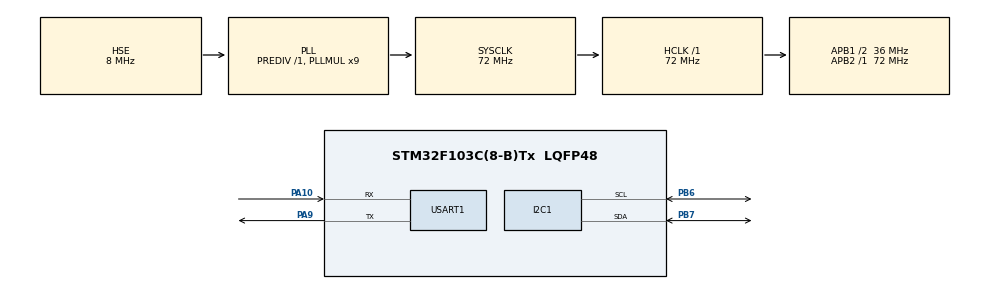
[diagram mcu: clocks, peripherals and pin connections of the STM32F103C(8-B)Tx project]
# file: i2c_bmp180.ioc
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Mcu.Family=STM32F1
Mcu.Name=STM32F103C(8-B)Tx
Mcu.Package=LQFP48
NVIC.PriorityGroup=NVIC_PRIORITYGROUP_4
PA10.Mode=Asynchronous
PA10.Signal=USART1_RX
PA13.Mode=Serial_Wire
PA13.Signal=SYS_JTMS-SWDIO
PA14.Mode=Serial_Wire
PA14.Signal=SYS_JTCK-SWCLK
PA9.Mode=Asynchronous
PA9.Signal=USART1_TX
PB6.Mode=I2C
PB6.Signal=I2C1_SCL
PB7.Mode=I2C
PB7.Signal=I2C1_SDA
PD0-OSC_IN.Mode=HSE-External-Oscillator
PD0-OSC_IN.Signal=RCC_OSC_IN
PD1-OSC_OUT.Mode=HSE-External-Oscillator
PD1-OSC_OUT.Signal=RCC_OSC_OUT
ProjectManager.HeapSize=0x200
ProjectManager.StackSize=0x400
ProjectManager.TargetToolchain=STM32CubeIDE
RCC.AHBFreq_Value=72000000
RCC.APB1CLKDivider=RCC_HCLK_DIV2
RCC.APB1Freq_Value=36000000
RCC.APB1TimFreq_Value=72000000
RCC.APB2Freq_Value=72000000
RCC.APB2TimFreq_Value=72000000
RCC.HCLKFreq_Value=72000000
RCC.PLLMUL=RCC_PLL_MUL9
RCC.PLLSourceVirtual=RCC_PLLSOURCE_HSE
RCC.SYSCLKFreq_VALUE=72000000
RCC.SYSCLKSource=RCC_SYSCLKSOURCE_PLLCLK
RCC.USBFreq_Value=72000000
USART1.VirtualMode=VM_ASYNC
board=custom

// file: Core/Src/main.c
/* USER CODE BEGIN Header */
/**
  ******************************************************************************
  * @file           : main.c
  * @brief          : BMP180 temperature/pressure reading on STM32F103C8
  ******************************************************************************
  */
/* USER CODE END Header */
#include "main.h"

/* USER CODE BEGIN Includes */
#include "bmp180.h"
#include <stdio.h>
#include <string.h>
/* USER CODE END Includes */

I2C_HandleTypeDef hi2c1;

UART_HandleTypeDef huart1;

/* USER CODE BEGIN PV */
BMP180_t bmp;
/* USER CODE END PV */

void SystemClock_Config(void);
static void MX_GPIO_Init(void);
static void MX_I2C1_Init(void);
static void MX_USART1_UART_Init(void);

int main(void)
{
  /* Reset of all peripherals, Initializes the Flash interface and the Systick. */
  HAL_Init();

  /* Configure the system clock */
  SystemClock_Config();

  /* Initialize all configured peripherals */
  MX_GPIO_Init();
  MX_I2C1_Init();
  MX_USART1_UART_Init();

  /* USER CODE BEGIN 2 */
  char msg[80];

  if (BMP180_Init(&bmp, &hi2c1, BMP180_OSS_3) != HAL_OK) {
      const char *err = "BMP180 not found! Wiring / pull-up check gara.\r\n";
      HAL_UART_Transmit(&huart1, (uint8_t *)err, strlen(err), 100);
  }
  /* USER CODE END 2 */

  /* Infinite loop */
  while (1)
  {
    /* USER CODE BEGIN 3 */
    int32_t t10, p;

    if (BMP180_ReadTemperature(&bmp, &t10) == HAL_OK &&
        BMP180_ReadPressure(&bmp, &p)      == HAL_OK)
    {
        /* integer printing -> printf float enable garnu pardaina */
        int32_t alt_cm = (int32_t)(BMP180_Altitude(p, 101325.0f) * 100.0f);

        int n = snprintf(msg, sizeof(msg),
                 "T=%ld.%ld C  P=%ld Pa  Alt=%ld.%02ld m\r\n",
                 t10 / 10, (t10 < 0 ? -t10 : t10) % 10,
                 p,
                 alt_cm / 100, (alt_cm < 0 ? -alt_cm : alt_cm) % 100);
        HAL_UART_Transmit(&huart1, (uint8_t *)msg, n, 100);
    }
    else
    {
        const char *e = "Read error\r\n";
        HAL_UART_Transmit(&huart1, (uint8_t *)e, strlen(e), 100);
    }

    HAL_GPIO_TogglePin(GPIOC, GPIO_PIN_13);
    HAL_Delay(1000);
    /* USER CODE END 3 */
  }
}

void SystemClock_Config(void)
{
  RCC_OscInitTypeDef RCC_OscInitStruct = {0};
  RCC_ClkInitTypeDef RCC_ClkInitStruct = {0};

  RCC_OscInitStruct.OscillatorType = RCC_OSCILLATORTYPE_HSE;
  RCC_OscInitStruct.HSEState = RCC_HSE_ON;
  RCC_OscInitStruct.HSEPredivValue = RCC_HSE_PREDIV_DIV1;
  RCC_OscInitStruct.HSIState = RCC_HSI_ON;
  RCC_OscInitStruct.PLL.PLLState = RCC_PLL_ON;
  RCC_OscInitStruct.PLL.PLLSource = RCC_PLLSOURCE_HSE;
  RCC_OscInitStruct.PLL.PLLMUL = RCC_PLL_MUL9;
  if (HAL_RCC_OscConfig(&RCC_OscInitStruct) != HAL_OK)
  {
    Error_Handler();
  }

  RCC_ClkInitStruct.ClockType = RCC_CLOCKTYPE_HCLK|RCC_CLOCKTYPE_SYSCLK
                              |RCC_CLOCKTYPE_PCLK1|RCC_CLOCKTYPE_PCLK2;
  RCC_ClkInitStruct.SYSCLKSource = RCC_SYSCLKSOURCE_PLLCLK;
  RCC_ClkInitStruct.AHBCLKDivider = RCC_SYSCLK_DIV1;
  RCC_ClkInitStruct.APB1CLKDivider = RCC_HCLK_DIV2;
  RCC_ClkInitStruct.APB2CLKDivider = RCC_HCLK_DIV1;

  if (HAL_RCC_ClockConfig(&RCC_ClkInitStruct, FLASH_LATENCY_2) != HAL_OK)
  {
    Error_Handler();
  }
}

static void MX_I2C1_Init(void)
{
  hi2c1.Instance = I2C1;
  hi2c1.Init.ClockSpeed = 100000;
  hi2c1.Init.DutyCycle = I2C_DUTYCYCLE_2;
  hi2c1.Init.OwnAddress1 = 0;
  hi2c1.Init.AddressingMode = I2C_ADDRESSINGMODE_7BIT;
  hi2c1.Init.DualAddressMode = I2C_DUALADDRESS_DISABLE;
  hi2c1.Init.OwnAddress2 = 0;
  hi2c1.Init.GeneralCallMode = I2C_GENERALCALL_DISABLE;
  hi2c1.Init.NoStretchMode = I2C_NOSTRETCH_DISABLE;
  if (HAL_I2C_Init(&hi2c1) != HAL_OK)
  {
    Error_Handler();
  }
}

static void MX_USART1_UART_Init(void)
{
  huart1.Instance = USART1;
  huart1.Init.BaudRate = 115200;
  huart1.Init.WordLength = UART_WORDLENGTH_8B;
  huart1.Init.StopBits = UART_STOPBITS_1;
  huart1.Init.Parity = UART_PARITY_NONE;
  huart1.Init.Mode = UART_MODE_TX_RX;
  huart1.Init.HwFlowCtl = UART_HWCONTROL_NONE;
  huart1.Init.OverSampling = UART_OVERSAMPLING_16;
  if (HAL_UART_Init(&huart1) != HAL_OK)
  {
    Error_Handler();
  }
}

static void MX_GPIO_Init(void)
{
  GPIO_InitTypeDef GPIO_InitStruct = {0};

  /* GPIO Ports Clock Enable */
  __HAL_RCC_GPIOC_CLK_ENABLE();
  __HAL_RCC_GPIOD_CLK_ENABLE();
  __HAL_RCC_GPIOA_CLK_ENABLE();
  __HAL_RCC_GPIOB_CLK_ENABLE();

  /* LED off initially (Blue Pill LED is active-low) */
  HAL_GPIO_WritePin(GPIOC, GPIO_PIN_13, GPIO_PIN_SET);

  /* PC13 as output */
  GPIO_InitStruct.Pin = GPIO_PIN_13;
  GPIO_InitStruct.Mode = GPIO_MODE_OUTPUT_PP;
  GPIO_InitStruct.Speed = GPIO_SPEED_FREQ_LOW;
  HAL_GPIO_Init(GPIOC, &GPIO_InitStruct);
}

void Error_Handler(void)
{
  __disable_irq();
  while (1)
  {
  }
}
